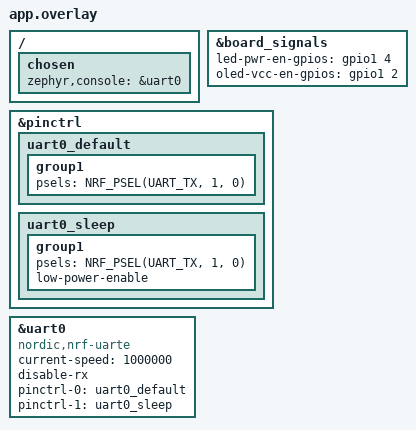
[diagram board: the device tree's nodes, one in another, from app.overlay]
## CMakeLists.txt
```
# SPDX-License-Identifier: Apache-2.0
# W2 firmware (Phase 2 plan section 2 W2, milestone W-fw; ADR-009 D7): the S4 brown-out reboot
# loop of dial-me-spinner docs/firmware.md, the old rule and the NEW-1 rule. A fixed BUILD_VERSION
# and no boot banner keep the workspace's `git describe` out of the image, so the image hash does
# not depend on the workspace.
cmake_minimum_required(VERSION 3.20.0)
set(BUILD_VERSION bb-dms-w2-oled-1)
# The out-of-tree board (../boards/dial/dial_me_spinner) and its bindings (../dts/bindings).
list(APPEND BOARD_ROOT ${CMAKE_CURRENT_LIST_DIR}/..)
list(APPEND DTS_ROOT ${CMAKE_CURRENT_LIST_DIR}/..)
find_package(Zephyr REQUIRED HINTS $ENV{ZEPHYR_BASE})
project(w2_oled)
target_sources(app PRIVATE src/main.c)
```

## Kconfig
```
# SPDX-License-Identifier: Apache-2.0
config W2_OLD_RULE
	bool "The old rule: enable the OLED boost at boot (the S4 reboot loop)"
	help
	  The one switch between w2_rule.elf (the NEW-1 rule: OLED_VCC_EN stays
	  low, the LEDs show the charging cue) and w2_old_rule.elf (OLED_VCC_EN
	  rises at every boot) (Phase 2 milestone W-fw).

config W2_START_DELAY_MS
	int "Delay from main() to the rule's enable (ms)"
	default 1
	help
	  The boot steps before section 7.2 step 22 that Phase 2 cannot run
	  (the charger's I2C setup, the OLED's SPI), as one sleep.

config W2_DIN_DELAY_MS
	int "The rule: delay from LED_PWR_EN high to P0.06 high (ms)"
	default 15
	help
	  At least 10 ms with P0.06 low after VLED is switched on
	  (firmware.md section 6.4, LED-DATA-V4), as in W1.

source "Kconfig.zephyr"
```

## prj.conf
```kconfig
# SPDX-License-Identifier: Apache-2.0
# GPIO, RESETREAS through the nrf_power HAL, and printk on the UARTE0 console (the log lines of
# ADR-008 D8). No regulator framework (the enables are plain GPIOs, as in W1), no logging
# subsystem and no boot banner (ADR-008 D5: no `git describe` in the image).
CONFIG_GPIO=y
CONFIG_REGULATOR=n
CONFIG_BOOT_BANNER=n
CONFIG_SERIAL=y
CONFIG_CONSOLE=y
CONFIG_UART_CONSOLE=y
CONFIG_PRINTK=y
CONFIG_LOG=n
```

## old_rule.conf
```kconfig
# w2_old_rule.elf: the uncapped boot, OLED_VCC_EN at every boot (Kconfig W2_OLD_RULE).
CONFIG_W2_OLD_RULE=y
```

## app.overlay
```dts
/*
 * SPDX-License-Identifier: Apache-2.0
 *
 * W2's additions to the board subset (Phase 2 milestone W-fw), transcribed from dial-me-spinner
 * docs/firmware.md section 3.1 (the board DTS draft) and section 1.3 (the pin table) at 6854d25:
 *   - board-signals: LED_PWR_EN (P1.04, U2's ON, R3 100 kOhm pull-down) and OLED_VCC_EN (P1.02,
 *     U21's ON, R25 100 kOhm pull-down: OLED_VIN -> TPS61040) as plain GPIO outputs, as in W1
 *     (the vled node deleted: P1.04 has one owner);
 *   - UARTE0, TX only on P1.00 at 1 Mbaud, as the console (the log, ADR-008 D8).
 * An application overlay, not the board file, so the E1-E3 images build exactly as before.
 */
/delete-node/ &vled;

/ {
	chosen {
		zephyr,console = &uart0;               /* TX-only log on P1.00 */
	};
};

&board_signals {
	led-pwr-en-gpios = <&gpio1 4 GPIO_ACTIVE_HIGH>;    /* LED_PWR_EN -> U2 TPS22917 ON */
	oled-vcc-en-gpios = <&gpio1 2 GPIO_ACTIVE_HIGH>;   /* OLED_VCC_EN -> U21 TPS22917 ON */
};

&pinctrl {
	uart0_default: uart0_default {
		group1 {
			psels = <NRF_PSEL(UART_TX, 1, 0)>;
		};
	};
	uart0_sleep: uart0_sleep {
		group1 {
			psels = <NRF_PSEL(UART_TX, 1, 0)>;
			low-power-enable;
		};
	};
};

&uart0 {
	compatible = "nordic,nrf-uarte";
	status = "okay";
	current-speed = <1000000>;
	disable-rx;
	pinctrl-0 = <&uart0_default>;
	pinctrl-1 = <&uart0_sleep>;
	pinctrl-names = "default", "sleep";
};
```

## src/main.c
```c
/*
 * SPDX-License-Identifier: Apache-2.0
 *
 * W2 firmware (Phase 2 plan section 2 W2 and milestone W-fw; ADR-009 D7): the S4 brown-out
 * reboot loop of dial-me-spinner docs/firmware.md (at 6854d25), USB at ILIM 100 mA with a dead
 * cell. Two images from one source:
 *
 *   w2_old_rule.elf (CONFIG_W2_OLD_RULE): the uncapped boot. W2_START_DELAY_MS after main()
 *          starts, OLED_VCC_EN (P1.02) rises (section 7.2 step 22: U21 TPS22917 connects VSYS to
 *          OLED_VIN and the TPS61040 boost starts, its surge collapsing VSYS). +3V3 falls below
 *          VBOR, the CPU resets, and the same boot enables the OLED again: the loop of the
 *          suite's strict xfail test_u21_turn_on_dead_battery_usb_100ma.
 *   w2_rule.elf: the NEW-1 rule (firmware.md section 6.3 "VBUS present but input limit still
 *          100 mA" and section 7.2): OLED_VCC_EN stays low unless the battery can supplement SYS
 *          (no BUVLO_STAT and VBAT_est >= 3.21 V from a battery-only reading in this power-up).
 *          Neither can be known here: Phase 2 has no TWIM bus device, so the firmware reads no
 *          STAT1 and has no battery-only reading (plan section 2 W1's recorded deviation). The
 *          supplement is therefore unknown and the OLED stays off; the LEDs show only the
 *          charging cue: LED_PWR_EN (P1.04) high at the same instant, and P0.06 (the cue's first
 *          frame, as in W1 and E1) W2_DIN_DELAY_MS later. The suite's passing
 *          ..._with_fw_rule[ILIM100-SYSREG4.5] case.
 *
 * Every boot reads RESETREAS, clears the bits it read (as the product's boot does, section 15)
 * and prints them with the rule on the console (UARTE0 TX on P1.00, the tap of ADR-008 D8): a
 * brown-out leaves no reset reason, so W2's old-rule check expects 0 after every reset (ADR-009
 * D7). The firmware keeps nothing in RAM across a reset (D7 keeps RAM; nothing here relies on it).
 *
 * POFCON is not used: W2 is about the OLED rule and the brown-out reset. In the suite's deck the
 * old rule's +3V3 crosses VBOR 3.83-4.09 ms after OLED_VCC_EN, inside firmware.md's 10 ms POFWARN
 * blanking of that edge (section 12.4), so a POF handler could not act before the reset; the
 * rule's +3V3 stays at 3.22 V or above. W1 is the POF case.
 */
#include <zephyr/kernel.h>
#include <zephyr/drivers/gpio.h>
#include <zephyr/sys/printk.h>
#include <hal/nrf_power.h>

static const struct gpio_dt_spec led_pwr_en =
	GPIO_DT_SPEC_GET(DT_NODELABEL(board_signals), led_pwr_en_gpios);
static const struct gpio_dt_spec led_din =
	GPIO_DT_SPEC_GET(DT_NODELABEL(board_signals), led_din_gpios);
static const struct gpio_dt_spec oled_vcc_en =
	GPIO_DT_SPEC_GET(DT_NODELABEL(board_signals), oled_vcc_en_gpios);

int main(void)
{
	uint32_t resetreas = nrf_power_resetreas_get(NRF_POWER);

	nrf_power_resetreas_clear(NRF_POWER, resetreas);
	if (!gpio_is_ready_dt(&led_pwr_en) || !gpio_is_ready_dt(&led_din) ||
	    !gpio_is_ready_dt(&oled_vcc_en)) {
		return 0;
	}
	(void)gpio_pin_configure_dt(&led_pwr_en, GPIO_OUTPUT_INACTIVE);
	(void)gpio_pin_configure_dt(&led_din, GPIO_OUTPUT_INACTIVE);
	(void)gpio_pin_configure_dt(&oled_vcc_en, GPIO_OUTPUT_INACTIVE);
	printk("w2: boot resetreas=0x%08x rule=%s\n", (unsigned int)resetreas,
	       IS_ENABLED(CONFIG_W2_OLD_RULE) ? "old" : "new");

	k_msleep(CONFIG_W2_START_DELAY_MS);

#ifdef CONFIG_W2_OLD_RULE
	/* The uncapped boot: the OLED boost on a 100 mA input with a dead cell. */
	(void)gpio_pin_set_dt(&oled_vcc_en, 1);
#else
	/* NEW-1: the supplement is unknown (no STAT1, no battery-only reading), so the OLED stays
	 * off and the LEDs show only the charging cue.
	 */
	(void)gpio_pin_set_dt(&led_pwr_en, 1);
	k_msleep(CONFIG_W2_DIN_DELAY_MS);
	(void)gpio_pin_set_dt(&led_din, 1);
#endif
	for (;;) {
		k_sleep(K_FOREVER);
	}
	return 0;
}
```
